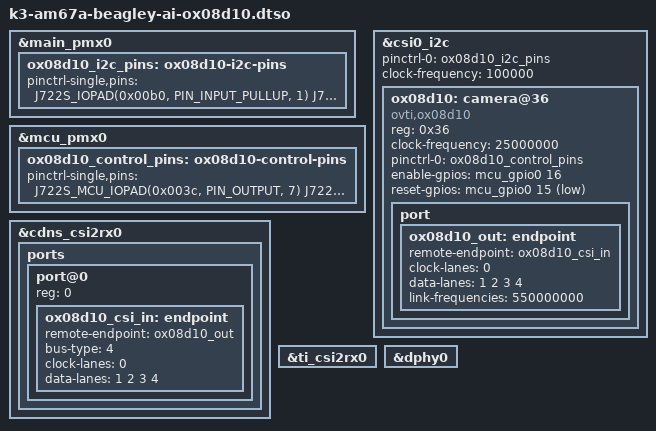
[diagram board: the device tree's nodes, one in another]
// SPDX-License-Identifier: GPL-2.0-only OR MIT
/* Direct CSI0 module. Load instead of the OX03H10/SerDes camera overlay.
 * Module must supply the 25 MHz oscillator required by the TI register table.
 */
/dts-v1/;
/plugin/;
#include <dt-bindings/gpio/gpio.h>
#include "k3-pinctrl.h"

&main_pmx0 {
	ox08d10_i2c_pins: ox08d10-i2c-pins {
		pinctrl-single,pins = <
			J722S_IOPAD(0x00b0, PIN_INPUT_PULLUP, 1) /* P22: I2C2_SCL */
			J722S_IOPAD(0x00b4, PIN_INPUT_PULLUP, 1) /* P23: I2C2_SDA */
		>;
	};
};
&mcu_pmx0 {
	ox08d10_control_pins: ox08d10-control-pins {
		pinctrl-single,pins = <
			J722S_MCU_IOPAD(0x003c, PIN_OUTPUT, 7) /* CSI0 pin 17 */
			J722S_MCU_IOPAD(0x0040, PIN_OUTPUT, 7) /* CSI0 pin 18 */
		>;
	};
};
&csi0_i2c {
	pinctrl-names = "default";
	pinctrl-0 = <&ox08d10_i2c_pins>;
	#address-cells = <1>;
	#size-cells = <0>;
	clock-frequency = <100000>;
	status = "okay";

	ox08d10: camera@36 {
		compatible = "ovti,ox08d10";
		reg = <0x36>;
		/* On-module oscillator, not a clock generated by the connector. */
		clock-frequency = <25000000>;
		pinctrl-names = "default";
		pinctrl-0 = <&ox08d10_control_pins>;
		enable-gpios = <&mcu_gpio0 16 GPIO_ACTIVE_HIGH>;
		reset-gpios = <&mcu_gpio0 15 GPIO_ACTIVE_LOW>;
		port {
			ox08d10_out: endpoint {
				remote-endpoint = <&ox08d10_csi_in>;
				clock-lanes = <0>;
				data-lanes = <1 2 3 4>;
				link-frequencies = /bits/ 64 <550000000>;
			};
		};
	};
};
&cdns_csi2rx0 {
	status = "okay";
	ports {
		#address-cells = <1>;
		#size-cells = <0>;
		port@0 {
			reg = <0>;
			status = "okay";
			ox08d10_csi_in: endpoint {
				remote-endpoint = <&ox08d10_out>;
				bus-type = <4>;
				clock-lanes = <0>;
				data-lanes = <1 2 3 4>;
			};
		};
	};
};
&ti_csi2rx0 { status = "okay"; };
&dphy0 { status = "okay"; };
